# AC7842x register map
Vendor: AutoChips; Series: AC78; File version: 1.0
CPU: CM4 r0p1, little endian, MPU, FPU, VTOR, 4 interrupt priority bits
Registers are 32-bit, read-write, reset 0x0 unless marked. A register's access mark holds for its fields unless they carry their own. Offsets are from the block's base; [hi:lo] are bit positions; {n}, {i} and the like mark numbered series; 'fields as' and 'values as' point back to an identical list.

## PWM0 — Pulse Width Modulation
Base 0x40080000
Same registers: PWM1 0x40080800, PWM2 0x40081000, PWM3 0x40081800, PWM4 0x40082000, PWM5 0x40082800
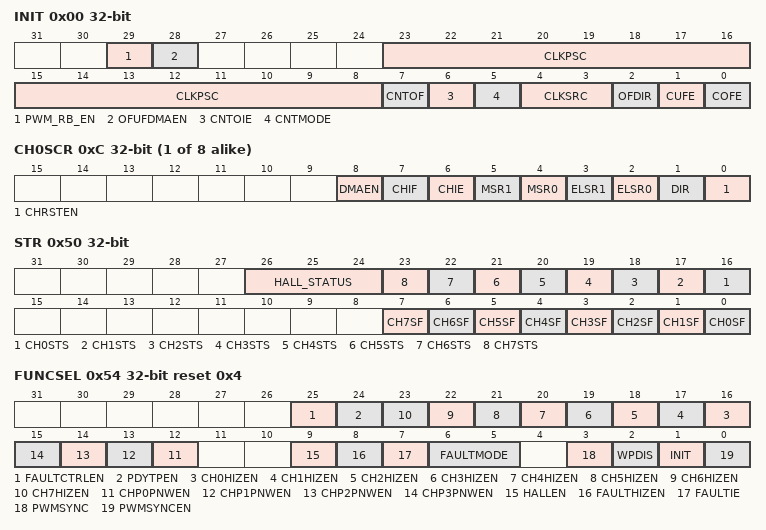
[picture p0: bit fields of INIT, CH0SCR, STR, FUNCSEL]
0x00 INIT — PWM Initialize, Include Clock and Prescale Setting
  [29] PWM_RB_EN — pwm read back enable
    0=disable; 1=enable
  [28] OFUFDMAEN — DMA request enable for overflow/underflow event occurs
    0=disable; 1=enable
  [23:8] CLKPSC — PWM Clk Prescale
  [7] CNTOF — Timer Overflow/Underflow Flag
    0=PWM counter has not overflowed; 1=PWM counter has overflowed
  [6] CNTOIE — Timer Overflow Interrupt Enable
    0=Disable TOF interrupts. Use software polling.; 1=Enable TOF interrupts. An interrupt is generated when TOF equals one.
  [5] CNTMODE — PWM Counter Mode Select
    0=PWM counter operates in up counting mode; 1=PWM counter operates in up-down counting mode
  [4:3] CLKSRC — Clock Source Selection
    0=No clock selected. This in effect disables the PWM counter.; 1=System clock; 2=Fixed frequency clock; 3=External clock
  [2] OFDIR — Counter Overflow/Underflow Dir
    0=underflow bit was set on the bottom of counting; 1=Overflow bit was set on the top of counting
  [1] CUFE — Counter Underflow event enable
    0=disable; 1=enable
  [0] COFE — Counter Overflow event enable
    0=disable; 1=enable
0x04 CNT — PWM Counter Value
  [15:0] COUNT
0x08 MCVR — PWM Counter Max Count Value Register
  [15:0] MCVR — Counter Max Count Value
{0xC+8i} CH{i}SCR (i=0..7) — Channel (n) Status And Control Register
  [8] DMAEN — DMA request enable for channel event
    0=disable; 1=enable
  [7] CHIF — Channel Interrupt Flag
    0=No channel event has occurred; 1=A Channel event has occurred
  [6] CHIE — Channel Interrupt Enable
    0=Disable channel interrupts. Use software polling.; 1=Enable channel interrupts
  [5] MSR1 — Channel Mode Select Register 1
  [4] MSR0 — Channel Mode Select Register 0
  [3] ELSR1 — Edge or Level Select Register 1
  [2] ELSR0 — Edge or Level Select Register 0
  [1] DIR — Match point direction
    0=Down count match; 1=Up count match
  [0] CHRSTEN — Channel event to reset counter enable
    0=disable; 1=enable
{0x10+8i} CH{i}V (i=0..7) — Channel (n) Value
  [15:0] CHCVAL — Channel Count Value
0x4C CNTIN — Counter Initial Value
  [15:0] CNTINIT — counter initial value
0x50 STR — Status Register
  [26:24] HALL_STATUS
  [n+16] CH{n}STS (n=0..7) — Channel {n} status
  [n] CH{n}SF (n=0..7) — Channel {n} Status Flag
    values as CH0SCR.CHIF
0x54 FUNCSEL reset 0x4 — PWM Features(Functions) Mode Selection Register
  [25] FAULTCTRLEN — Enable restore 100% or 0% duty output after fault is clear
    0=Keep safe output after fault is clear; 1=Restore to 100% or 0% duty output after fault is clear
  [24] PDYTPEN — PWM duty type select in combined center-aligned PWM mode
    0=Cnv=Cn+1V=FTM CNTIN,output 0% duty cycle; Cnv=Cn+1V=FTM MOD,output 100% duty cycle; 1=Cnv=Cn+1V=FTM CNTIN,output 100% duty cycle; Cnv=Cn+1V=FTM MOD,output 0% duty cycle
  [n+16] CH{n}HIZEN (n=0..7) — channel {n} HiZ output enable
  [n+12] CHP{n}PNWEN (n=0..3) — channel pair {n} positive and negative width measurement
  [9] HALLEN — HALL enable control in capture mode
    0=disable hall input capture function; 1=enable hall input capture function
  [8] FAULTHIZEN — Enable HiZ Output when fault input event occurs
    0=disable; 1=enable,hiz output
  [7] FAULTIE — Fault Interrupt Enable
    0=Fault control interrupt is disabled; 1=Fault control interrupt is enabled
  [6:5] FAULTMODE — Fault Control Mode
    0=Fault control is disabled for all channels; 1=Fault control is enabled for even channels only (channels 0, 2, 4, and 6), and the selected mode is the manual fault clearing; 2=Fault control is enabled for all channels, and the selected mode is the manual fault clearing; 3=Fault control is enabled for all channels, and the selected mode is the automatic fault clearing
  [3] PWMSYNC — PWM Synchronization Mode
    0=No restrictions. Software and hardware triggers can be used by MOD, CnV, OUTMASK, and PWM counter synchronization.; 1=Software trigger can only be used by MOD and CnV synchronization, and hardware triggers can only be used by OUTMASK and PWM counter synchronization
  [2] WPDIS — Write Protection Disable
    0=Write protection is enabled; 1=Write protection is disabled
  [1] INIT — Initialize The Channels Output
  [0] PWMSYNCEN — PWM Synchronization functio Enable
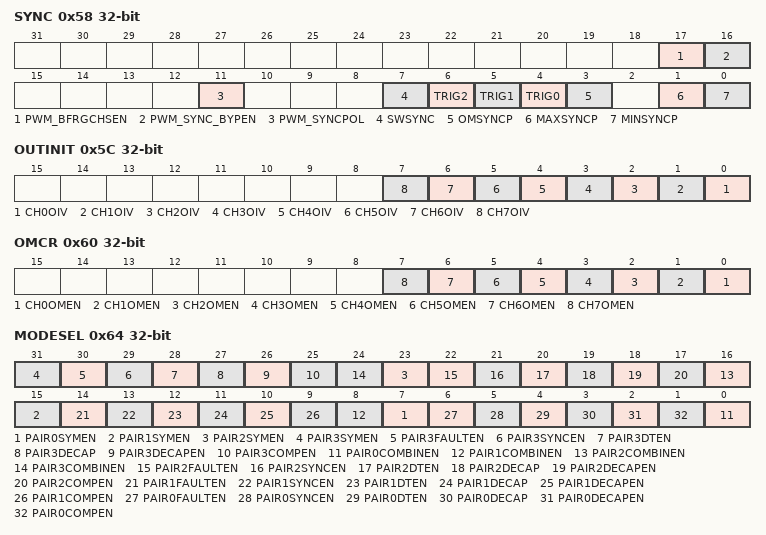
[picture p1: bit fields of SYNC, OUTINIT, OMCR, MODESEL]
0x58 SYNC — Synchronization
  [17] PWM_BFRGCHSEN — CnV/CNTIN/Mod buffer and register choosing bit
    0=CnV/CNTIN/Mod buffer is read by user through corresponding CnV/CNTIN/Mod Address; 1=CnV/CNTIN/Mod register is read by user through corresponding CnV/CNTIN/Mod Address
  [16] PWM_SYNC_BYPEN — CnV/CNTIN/Mod bypass synchronization mechanism enable bit
    0=write to CnV/CNTIN/Mod buffer and update to CnV/CNTIN/Mod register based on synchronization mechanism; 1=write to CnV/CNTIN/Mod buffer and update to CnV/CNTIN/Mod register immediately ignoring synchronization mechanism
  [11] PWM_SYNCPOL — select when the POL register is updated with the value of its buffer
    0=POL register is updated with the value of its buffer in all rising edges of the system clock; 1=POL register is updated with the value of its buffer only by the PWM synchronization
  [7] SWSYNC — PWM Synchronization Software Trigger
    0=Software trigger is not selected; 1=Software trigger is selected
  [6] TRIG2 — PWM Synchronization Hardware Trigger 2
    0=Trigger is disabled; 1=Trigger is enabled
  [5] TRIG1 — PWM Synchronization Hardware Trigger 1
    0=Trigger is disabled; 1=Trigger is enabled
  [4] TRIG0 — PWM Synchronization Hardware Trigger 0
    0=Trigger is disabled; 1=Trigger is enabled
  [3] OMSYNCP — Output Mask Synchronization
    0=OUTMASK register is updated with the value of its buffer in all rising edges of the system clock; 1=OUTMASK register is updated with the value of its buffer only by the PWM synchronization
  [1] MAXSYNCP — Maximum Loading Point Enable
    0=The maximum loading point is disabled; 1=The maximum loading point is enabled
  [0] MINSYNCP — Minimum Loading Point Enable
    0=The minimum loading point is disabled; 1=The minimum loading point is enabled
0x5C OUTINIT — Initial State For Channels Output
  [all] fields
    0=The initialization value is 0; 1=The initialization value is 1
  [n] CH{n}OIV (n=0..7) — Channel {n} Output Initialization Value
0x60 OMCR — Output Mask Control Register
  [all] fields
    0=Channel output is not masked. It continues to operate normally.; 1=Channel output is masked. It is forced to its inactive state.
  [n] CH{n}OMEN (n=0..7) — Channel {n} Output Mask
0x64 MODESEL — PWM Function Mode Selection
  [8n+7] PAIR{n}SYMEN (n=0..3) — Symmetric configure for channel pair{n} CnV/Cn+1V
    0=disable symmetric configuration,i.e.user only just configure CnV or Cn+1V; 1=enable symmetric configuration,i.e.user should configure CnV and Cn+1V respectively
  [30] PAIR3FAULTEN — Fault Control Enable for Pair3
    0=The fault control in this pair of channels is disabled; 1=The fault control in this pair of channels is enabled
  [29] PAIR3SYNCEN — Synchronization Enable for Pair3
    0=The PWM synchronization in this pair of channels is disabled; 1=The PWM synchronization in this pair of channels is enabled
  [28] PAIR3DTEN — Deadtime Enable For Pair3
    0=The deadtime insertion in this pair of channels is disabled; 1=The deadtime insertion in this pair of channels is enabled
  [27] PAIR3DECAP — Dual Edge Capture Mode Captures For Pair3
    0=The dual edge captures are inactive; 1=The dual edge captures are active
  [26] PAIR3DECAPEN — Dual Edge Capture Mode Enable For Pair3
    0=The Dual Edge Capture mode in this pair of channels is disabled; 1=The Dual Edge Capture mode in this pair of channels is enabled
  [25] PAIR3COMPEN — Complement Of Channel (n) For Pair3
    0=The channel 7 output is the same as the channel 6 output; 1=The channel 7 output is the complement of the channel 6 output
  [8n] PAIR{n}COMBINEN (n=0..3) — Combine Channels For Pair{n}
    0=Channels {2n} and {2n+1} are independent; 1=Channels {2n} and {2n+1} are combined
  [22] PAIR2FAULTEN — Fault Control Enable for Pair2
    values as PAIR3FAULTEN
  [21] PAIR2SYNCEN — Synchronization Enable for Pair2
    values as PAIR3SYNCEN
  [20] PAIR2DTEN — Deadtime Enable For Pair2
    values as PAIR3DTEN
  [19] PAIR2DECAP — Dual Edge Capture Mode Captures For Pair2
    values as PAIR3DECAP
  [18] PAIR2DECAPEN — Dual Edge Capture Mode Enable For Pair2
    values as PAIR3DECAPEN
  [17] PAIR2COMPEN — Complement Of Channel (n) For Pair2
    0=The channel 5 output is the same as the channel 4 output; 1=The channel 5 output is the complement of the channel 4 output
  [14] PAIR1FAULTEN — Fault Control Enable For Pair1
    values as PAIR3FAULTEN
  [13] PAIR1SYNCEN — Synchronization Enable For Pair1
    values as PAIR3SYNCEN
  [12] PAIR1DTEN — Deadtime Enable For Pair1
    values as PAIR3DTEN
  [11] PAIR1DECAP — Dual Edge Capture Mode Captures For Pair1
    values as PAIR3DECAP
  [10] PAIR1DECAPEN — Dual Edge Capture Mode Enable For Pair1
    values as PAIR3DECAPEN
  [9] PAIR1COMPEN — Complement Of Channel (n) For Pair1
    0=The channel 3 output is the same as the channel 2 output; 1=The channel 3 output is the complement of the channel 2 output
  [6] PAIR0FAULTEN — Fault Control Enable for Pair0
    values as PAIR3FAULTEN
  [5] PAIR0SYNCEN — Synchronization Enable for Pair0
    values as PAIR3SYNCEN
  [4] PAIR0DTEN — Deadtime Enable for Pair0
    values as PAIR3DTEN
  [3] PAIR0DECAP — Dual Edge Capture Mode Captures for Pair0
    values as PAIR3DECAP
  [2] PAIR0DECAPEN — Dual Edge Capture Mode Enable for Pair0
    values as PAIR3DECAPEN
  [1] PAIR0COMPEN — Complement Channels for Pair0
    0=The channel 1 output is the same as the channel 0 output; 1=The channel 1 output is the complement of the channel 0 output
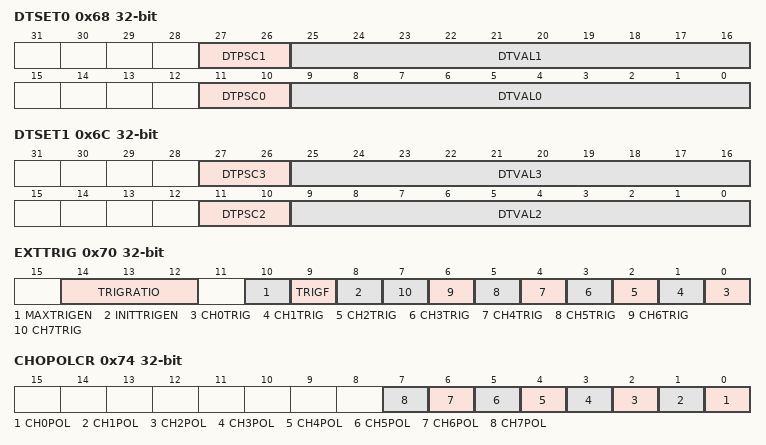
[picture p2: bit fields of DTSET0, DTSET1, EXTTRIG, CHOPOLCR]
0x68 DTSET0 — Deadtime Insertion Control 0
  [27:26] DTPSC1 — Deadtime Prescaler Value 1 for channel pair 1
    0b0x=Divide the system clock by 1; 2=Divide the system clock by 4; 3=Divide the system clock by 16
  [25:16] DTVAL1 — Deadtime Value 1 for channel pair 1
  [11:10] DTPSC0 — Deadtime Prescaler Value 0 for channel pair 0
    values as DTPSC1
  [9:0] DTVAL0 — Deadtime Value 0 for channel pair 0
0x6C DTSET1 — Deadtime Insertion Control 1
  [27:26] DTPSC3 — Deadtime Prescaler Value 4 for channel pair 4
    values as DTSET0.DTPSC1
  [25:16] DTVAL3 — Deadtime Value 3 for channel pair 3
  [11:10] DTPSC2 — Deadtime Prescaler Value 2 for channel pair 2
    values as DTSET0.DTPSC1
  [9:0] DTVAL2 — Deadtime Value 2 for channel pair 2
0x70 EXTTRIG — PWM External Trigger
  [14:12] TRIGRATIO — Trigger Ratio for init/max/match trigger
  [10] MAXTRIGEN — Max Trigger Enable
    0=disable; 1=enable
  [9] TRIGF — Channel Trigger Flag
    0=No channel trigger was generated; 1=A channel trigger was generated
  [8] INITTRIGEN — Initialization Trigger Enable
    0=The generation of initialization trigger is disabled; 1=The generation of initialization trigger is enabled
  [n] CH{n}TRIG (n=0..7) — Channel {n} Trigger Enable
    0=The generation of the channel trigger is disabled; 1=The generation of the channel trigger is enabled
0x74 CHOPOLCR — Channel Output Polarity Register
  [all] fields
    0=The channel polarity is active high; 1=The channel polarity is active low
  [n] CH{n}POL (n=0..7) — Channel {n} Polarity
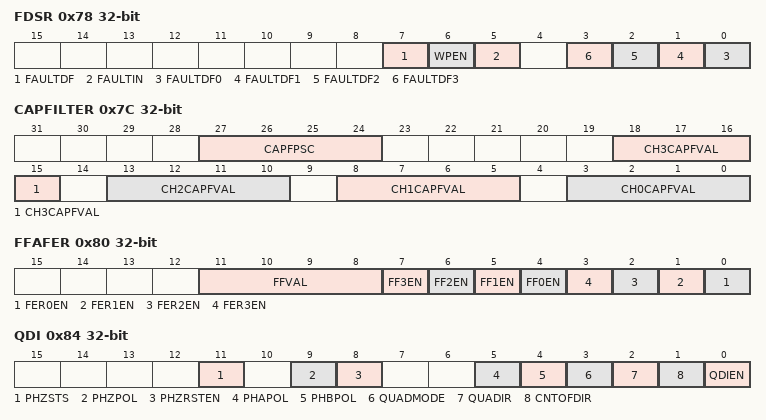
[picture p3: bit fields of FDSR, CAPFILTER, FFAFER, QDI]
0x78 FDSR — Fault Detect Status Register
  [7] FAULTDF — Fault Detection Flag
    0=No fault condition was detected; 1=A fault condition was detected
  [6] WPEN — Write Protection Enable
    0=Write protection is disabled. Write protected bits can be written.; 1=Write protection is enabled. Write protected bits cannot be written.
  [5] FAULTIN ro — Fault Inputs
    0=The logic OR of the enabled fault inputs is 0; 1=The logic OR of the enabled fault inputs is 1
  [n] FAULTDF{n} (n=0..3) — Fault Detection Flag {n}
    0=No fault condition was detected at the fault input; 1=A fault condition was detected at the fault input
0x7C CAPFILTER — Input Capture Filter Control
  [27:24] CAPFPSC — Channel Input Filter And Fault input filter prescaler
  [5n+3:5n] CH{n}CAPFVAL (n=0..3) — Channel {n} Input Filter
0x80 FFAFER — Fault Filter and Fault Enable Register
  [11:8] FFVAL — Fault Input Filter
  [n+4] FF{n}EN (n=0..3) — Fault Input {n} Filter Enable
    0=Fault input filter is disabled; 1=Fault input filter is enabled
  [n] FER{n}EN (n=0..3) — Fault Input {n} Enable
    0=Fault input is disabled; 1=Fault input is enabled
0x84 QDI — Quadrature Decoder Interface Configuration Register
  [11] PHZSTS — Phase Z Status
    0=Phase Z event has not occurred; 1=Phase Z event has occurred and write 0 to clear
  [9] PHZPOL — Phase Z Input Polarity
    0=Normal polarity; 1=Inverted polarity
  [8] PHZRSTEN — Determine whether to reset PWM Counter when Phase Z event Occurs
    0=disable; 1=enable
  [5] PHAPOL — Phase A Input Polarity
    0=Normal polarity; 1=Inverted polarity
  [4] PHBPOL — Phase B Input Polarity
    0=Normal polarity; 1=Inverted polarity
  [3] QUADMODE — Quadrature Decoder Mode
    0=Phase A and phase B encoding mode; 1=Count and direction encoding mode
  [2] QUADIR ro — Counting Direction In Quadrature Decoder Mode
    0=Counting direction is decreasing; 1=Counting direction is increasing
  [1] CNTOFDIR ro — Overflow Direction
    0=Set on the bottom of counting; 1=Set on the top of counting
  [0] QDIEN — Quadrature Decoder Mode Enable
    0=Quadrature Decoder is Disable; 1=Quadrature Decoder is Enable
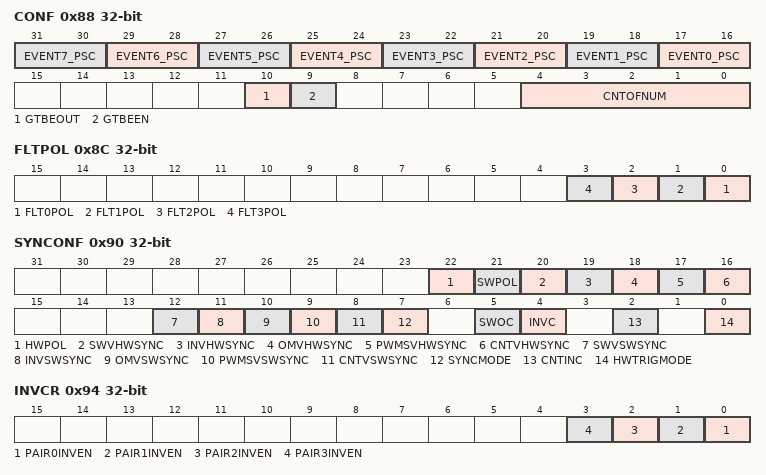
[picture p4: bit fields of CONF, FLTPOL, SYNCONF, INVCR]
0x88 CONF — Configuration
  [2n+17:2n+16] EVENT{n}_PSC (n=0..7) — Channel{n} input event PSC
    0=Event divided by 1; 1=Event divided by 2; 2=Event divided by 4; 3=Event divided by 8
  [10] GTBEOUT — Global Time Base Output
    0=A Global time base signal generation is disabled; 1=A Global time base signal generation is enabled
  [9] GTBEEN — Global Time Base Enable
    0=Use of an external Global time base is disabled; 1=Use of an external Global time base is enabled
  [4:0] CNTOFNUM — Count Overflow Flag Number
0x8C FLTPOL — PWM Fault Input Polarity
  [all] fields
    0=The fault input polarity is active high; 1=The fault input polarity is active low
  [n] FLT{n}POL (n=0..3) — Fault Input {n} Polarity
0x90 SYNCONF — Synchronization Configuration
  [22] HWPOL — Channel POL synchronization is activated by a hardware trigger
    0=The hardware trigger does not activate the POL register synchronization; 1=The hardware trigger activates POL register synchronization
  [21] SWPOL — Channel POL synchronization is activated by a software trigger
    0=The software trigger does not activate the POL register synchronization; 1=The software trigger activates POL register synchronization
  [20] SWVHWSYNC — Software Output Control synchronization is activated by the hardware trigger
    0=A hardware trigger does not activate the SWOCTRL register synchronization; 1=A hardware trigger activates the SWOCTRL register synchronization
  [19] INVHWSYNC — Inverting control synchronization is activated by the hardware trigger
    0=A hardware trigger does not activate the INVCTRL register synchronization; 1=A hardware trigger activates the INVCTRL register synchronization
  [18] OMVHWSYNC — Output Mask synchronization is activated by the hardware trigger
    0=A hardware trigger does not activate the OUTMASK register synchronization; 1=A hardware trigger activates the OUTMASK register synchronization
  [17] PWMSVHWSYNC — MOD,CNTIN,and CV registers synchronization is activated by the hardware trigger
    0=A hardware trigger does not activate MOD, CNTIN, and CV registers synchronization; 1=A hardware trigger activates MOD, CNTIN, and CV registers synchronization
  [16] CNTVHWSYNC — PWM Counter synchronization is activated by the hardware trigger
    0=A hardware trigger does not activate the PWM counter synchronization; 1=A hardware trigger activates the PWM counter synchronization
  [12] SWVSWSYNC — Software Output Control synchronization is activated by the software trigger
    0=The software trigger does not activate the SWOCTRL register synchronization; 1=The software trigger activates the SWOCTRL register synchronization
  [11] INVSWSYNC — Inverting control synchronization is activated by the software trigger
    0=The software trigger does not activate the INVCTRL register synchronization; 1=The software trigger activates the INVCTRL register synchronization
  [10] OMVSWSYNC — Output Mask synchronization is activated by the software trigger
    0=The software trigger does not activate the OUTMASK register synchronization; 1=The software trigger activates the OUTMASK register synchronization
  [9] PWMSVSWSYNC — MOD,CNTIN,and CV registers synchronization is activated by the software trigger
    0=The software trigger does not activate MOD, CNTIN, and CV registers synchronization; 1=The software trigger activates MOD, CNTIN, and CV registers synchronization
  [8] CNTVSWSYNC — PWM Counter synchronization is activated by the software trigger
    0=The software trigger does not activate the PWM counter synchronization; 1=The software trigger activates the PWM counter synchronization
  [7] SYNCMODE — Synchronization Mode
    0=Legacy PWM synchronization is selected; 1=Enhanced PWM synchronization is selected
  [5] SWOC — SWOCTRL Register Synchronization
    0=SWOCTRL register is updated with its buffer value at all rising edges of system clock; 1=SWOCTRL register is updated with its buffer value by the PWM synchronization
  [4] INVC — INVCTRL Register Synchronization
    0=INVCTRL register is updated with its buffer value at all rising edges of system clock; 1=INVCTRL register is updated with its buffer value by the PWM synchronization
  [2] CNTINC — CNTIN Register Synchronization
    0=CNTIN register is updated with its buffer value at all rising edges of system clock; 1=CNTIN register is updated with its buffer value by the PWM synchronization
  [0] HWTRIGMODE — Hardware Trigger Mode
    0=PWM clears the TRIGj bit when the hardware trigger j is detected; 1=PWM does not clear the TRIGj bit when the hardware trigger j is detected
0x94 INVCR — PWM Inverse Control Register
  [all] fields
    0=Inverting is disabled; 1=Inverting is enabled
  [n] PAIR{n}INVEN (n=0..3) — Pair Channels {n} Inverting Enable
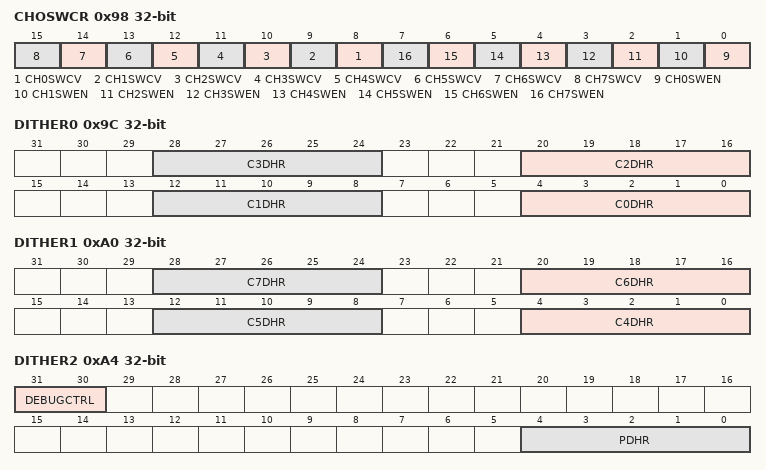
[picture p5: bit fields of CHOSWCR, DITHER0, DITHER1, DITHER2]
0x98 CHOSWCR — PWM CHannel Software Output Control Register
  [n+8] CH{n}SWCV (n=0..7) — Channel {n} Software Output Control Value
    0=The software output control forces 0 to the channel output; 1=The software output control forces 1 to the channel output
  [n] CH{n}SWEN (n=0..7) — Channel {n} Software Output Control Enable
    0=The channel output is not affected by software output control; 1=The channel output is affected by software output control
0x9C DITHER0 — Dither function register 0
  [8n+4:8n] C{n}DHR (n=0..3) — Channel {n} dither value or fraction match value
0xA0 DITHER1 — Dither function register 1
  [8n-28:8n-32] C{n}DHR (n=4..7) — Channel {n} dither value or fraction match value
0xA4 DITHER2 — Dither function register 2
  [31:30] DEBUGCTRL — PWM behavior control when the chip goes into debug mode
  [4:0] PDHR — Period dither value or PWM Counter fraction value
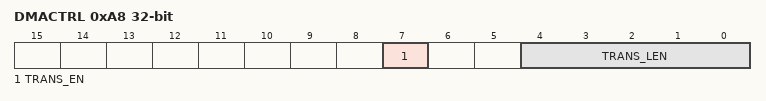
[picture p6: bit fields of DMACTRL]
0xA8 DMACTRL — DMA Control Register
  [7] TRANS_EN — PWM DMALGH enable
  [4:0] TRANS_LEN — Determine the dma transfer length for PWM dma reg clearing
